# M2Sxxx register map
Vendor: Microsemi; Series: SmartFusion2; File version: 2.0.32
CPU: CM3 r2p1, little endian, MPU, no FPU, 4 interrupt priority bits
Registers are 32-bit, read-write, no defined reset value unless marked. A register's access mark holds for its fields unless they carry their own. Offsets are from the block's base; [hi:lo] are bit positions; {n}, {i} and the like mark numbered series.

## Ethernet_MAC — No description provided for this peripheral
Base 0x40041000
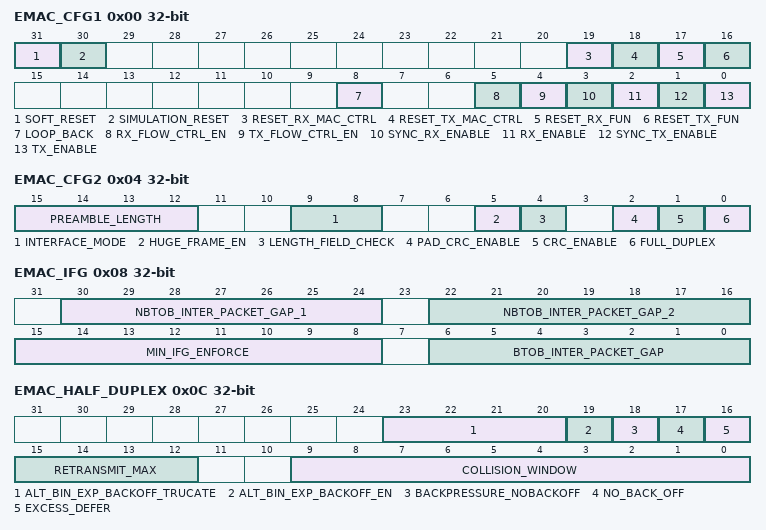
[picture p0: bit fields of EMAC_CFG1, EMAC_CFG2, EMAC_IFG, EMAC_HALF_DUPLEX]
0x00 EMAC_CFG1 — No description provided for this register
  [31] SOFT_RESET — No description provided for this field
  [30] SIMULATION_RESET — No description provided for this field
  [19] RESET_RX_MAC_CTRL — No description provided for this field
  [18] RESET_TX_MAC_CTRL — No description provided for this field
  [17] RESET_RX_FUN — No description provided for this field
  [16] RESET_TX_FUN — No description provided for this field
  [8] LOOP_BACK — No description provided for this field
  [5] RX_FLOW_CTRL_EN — No description provided for this field
  [4] TX_FLOW_CTRL_EN — No description provided for this field
  [3] SYNC_RX_ENABLE — No description provided for this field
  [2] RX_ENABLE — No description provided for this field
  [1] SYNC_TX_ENABLE — No description provided for this field
  [0] TX_ENABLE — No description provided for this field
0x04 EMAC_CFG2 — No description provided for this register
  [15:12] PREAMBLE_LENGTH — No description provided for this field
  [9:8] INTERFACE_MODE — No description provided for this field
  [5] HUGE_FRAME_EN — No description provided for this field
  [4] LENGTH_FIELD_CHECK — No description provided for this field
  [2] PAD_CRC_ENABLE — No description provided for this field
  [1] CRC_ENABLE — No description provided for this field
  [0] FULL_DUPLEX — No description provided for this field
0x08 EMAC_IFG — No description provided for this register
  [30:24] NBTOB_INTER_PACKET_GAP_1 — No description provided for this field
  [22:16] NBTOB_INTER_PACKET_GAP_2 — No description provided for this field
  [15:8] MIN_IFG_ENFORCE — No description provided for this field
  [6:0] BTOB_INTER_PACKET_GAP — No description provided for this field
0x0C EMAC_HALF_DUPLEX — No description provided for this register
  [23:20] ALT_BIN_EXP_BACKOFF_TRUCATE — No description provided for this field
  [19] ALT_BIN_EXP_BACKOFF_EN — No description provided for this field
  [18] BACKPRESSURE_NOBACKOFF — No description provided for this field
  [17] NO_BACK_OFF — No description provided for this field
  [16] EXCESS_DEFER — No description provided for this field
  [15:12] RETRANSMIT_MAX — No description provided for this field
  [9:0] COLLISION_WINDOW — No description provided for this field
0x10 EMAC_FRAME_LENGTH — No description provided for this register
  [15:0] MAX_FRAME_LENGTH — No description provided for this field
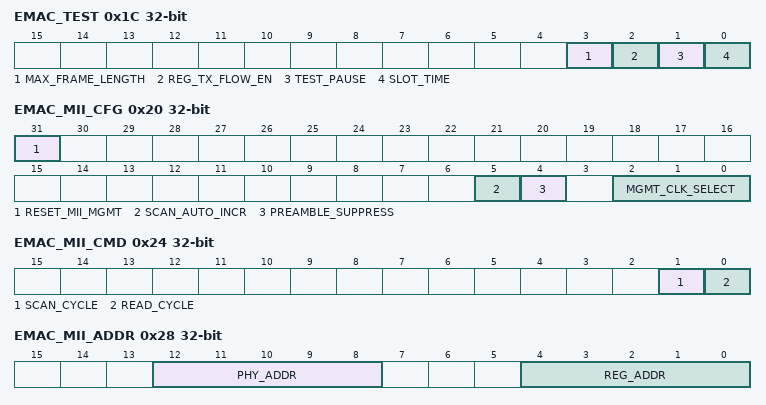
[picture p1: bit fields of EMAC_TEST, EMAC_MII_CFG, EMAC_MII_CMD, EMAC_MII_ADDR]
0x1C EMAC_TEST — No description provided for this register
  [3] MAX_FRAME_LENGTH — No description provided for this field
  [2] REG_TX_FLOW_EN — No description provided for this field
  [1] TEST_PAUSE — No description provided for this field
  [0] SLOT_TIME — No description provided for this field
0x20 EMAC_MII_CFG — No description provided for this register
  [31] RESET_MII_MGMT — No description provided for this field
  [5] SCAN_AUTO_INCR — No description provided for this field
  [4] PREAMBLE_SUPPRESS — No description provided for this field
  [2:0] MGMT_CLK_SELECT — No description provided for this field
0x24 EMAC_MII_CMD — No description provided for this register
  [1] SCAN_CYCLE — No description provided for this field
  [0] READ_CYCLE — No description provided for this field
0x28 EMAC_MII_ADDR — No description provided for this register
  [12:8] PHY_ADDR — No description provided for this field
  [4:0] REG_ADDR — No description provided for this field
0x2C EMAC_MII_CTRL — No description provided for this register
  [15:0] MII_MGMT_CTRL wo — No description provided for this field
0x30 EMAC_MII_STATUS — No description provided for this register
  [15:0] MII_MGMT_STATUS ro — No description provided for this field
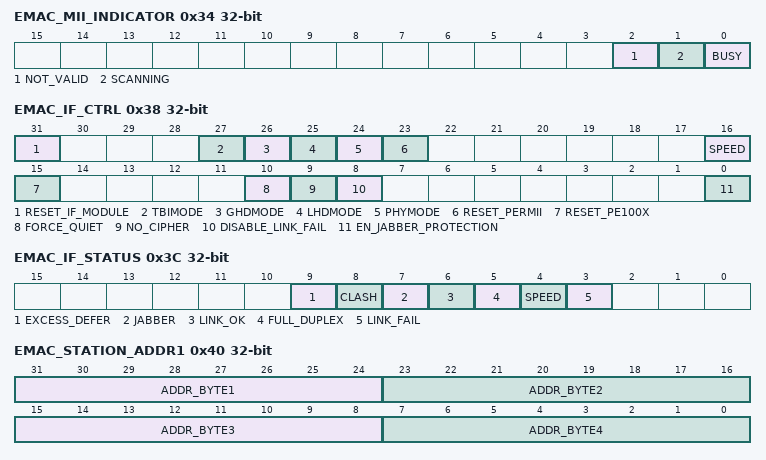
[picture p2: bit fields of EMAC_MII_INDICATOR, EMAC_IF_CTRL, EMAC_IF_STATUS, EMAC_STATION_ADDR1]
0x34 EMAC_MII_INDICATOR — No description provided for this register
  [2] NOT_VALID ro — No description provided for this field
  [1] SCANNING ro — No description provided for this field
  [0] BUSY ro — No description provided for this field
0x38 EMAC_IF_CTRL — No description provided for this register
  [31] RESET_IF_MODULE — No description provided for this field
  [27] TBIMODE — No description provided for this field
  [26] GHDMODE — No description provided for this field
  [25] LHDMODE — No description provided for this field
  [24] PHYMODE — No description provided for this field
  [23] RESET_PERMII — No description provided for this field
  [16] SPEED — No description provided for this field
  [15] RESET_PE100X — No description provided for this field
  [10] FORCE_QUIET — No description provided for this field
  [9] NO_CIPHER — No description provided for this field
  [8] DISABLE_LINK_FAIL — No description provided for this field
  [0] EN_JABBER_PROTECTION — No description provided for this field
0x3C EMAC_IF_STATUS — No description provided for this register
  [9] EXCESS_DEFER ro — No description provided for this field
  [8] CLASH ro — No description provided for this field
  [7] JABBER ro — No description provided for this field
  [6] LINK_OK ro — No description provided for this field
  [5] FULL_DUPLEX ro — No description provided for this field
  [4] SPEED ro — No description provided for this field
  [3] LINK_FAIL ro — No description provided for this field
0x40 EMAC_STATION_ADDR1 — No description provided for this register
  [39-8n:32-8n] ADDR_BYTE{n} (n=1..4) — No description provided for this field
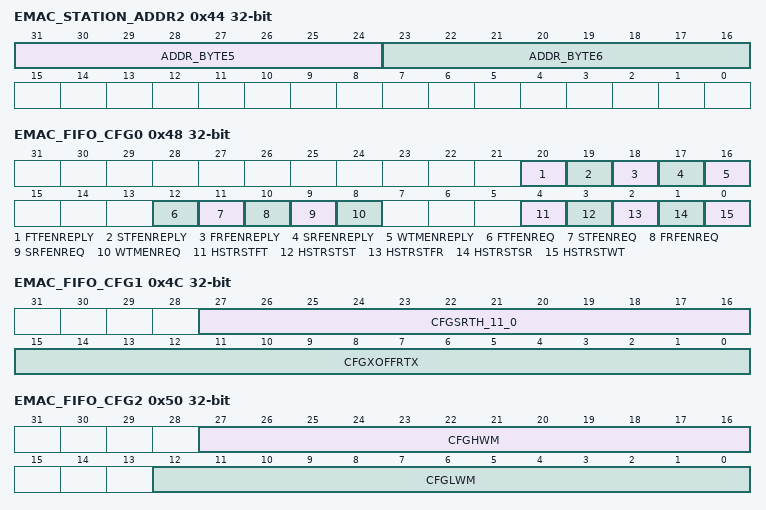
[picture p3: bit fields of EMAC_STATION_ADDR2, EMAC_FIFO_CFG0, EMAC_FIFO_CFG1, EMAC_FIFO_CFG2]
0x44 EMAC_STATION_ADDR2 — No description provided for this register
  [31:24] ADDR_BYTE5 — No description provided for this field
  [23:16] ADDR_BYTE6 — No description provided for this field
0x48 EMAC_FIFO_CFG0 — No description provided for this register
  [20] FTFENREPLY — No description provided for this field
  [19] STFENREPLY — No description provided for this field
  [18] FRFENREPLY — No description provided for this field
  [17] SRFENREPLY — No description provided for this field
  [16] WTMENREPLY — No description provided for this field
  [12] FTFENREQ — No description provided for this field
  [11] STFENREQ — No description provided for this field
  [10] FRFENREQ — No description provided for this field
  [9] SRFENREQ — No description provided for this field
  [8] WTMENREQ — No description provided for this field
  [4] HSTRSTFT — No description provided for this field
  [3] HSTRSTST — No description provided for this field
  [2] HSTRSTFR — No description provided for this field
  [1] HSTRSTSR — No description provided for this field
  [0] HSTRSTWT — No description provided for this field
0x4C EMAC_FIFO_CFG1 — No description provided for this register
  [27:16] CFGSRTH_11_0 — No description provided for this field
  [15:0] CFGXOFFRTX — No description provided for this field
0x50 EMAC_FIFO_CFG2 — No description provided for this register
  [27:16] CFGHWM — No description provided for this field
  [12:0] CFGLWM — No description provided for this field
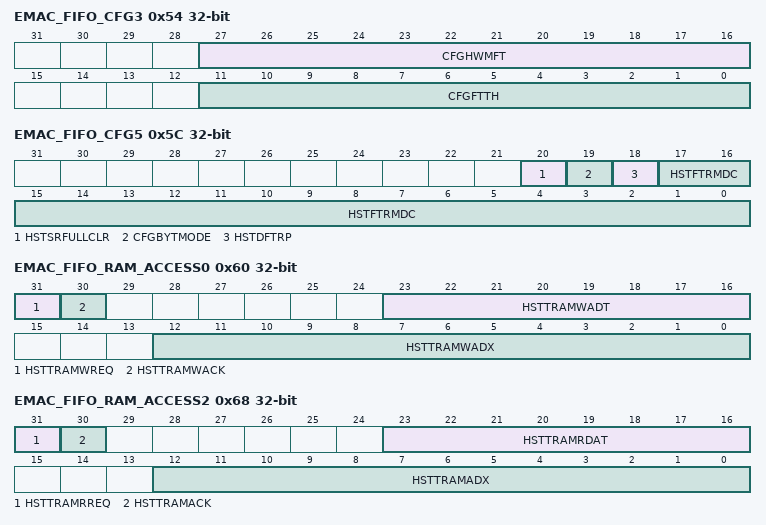
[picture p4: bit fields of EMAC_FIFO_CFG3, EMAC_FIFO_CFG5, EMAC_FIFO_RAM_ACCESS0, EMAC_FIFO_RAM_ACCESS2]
0x54 EMAC_FIFO_CFG3 — No description provided for this register
  [27:16] CFGHWMFT — No description provided for this field
  [11:0] CFGFTTH — No description provided for this field
0x58 EMAC_FIFO_CFG4 — No description provided for this register
  [17:0] HSTFTRFM — No description provided for this field
0x5C EMAC_FIFO_CFG5 — No description provided for this register
  [20] HSTSRFULLCLR — No description provided for this field
  [19] CFGBYTMODE — No description provided for this field
  [18] HSTDFTRP — No description provided for this field
  [17:0] HSTFTRMDC — No description provided for this field
0x60 EMAC_FIFO_RAM_ACCESS0 — No description provided for this register
  [31] HSTTRAMWREQ — No description provided for this field
  [30] HSTTRAMWACK — No description provided for this field
  [23:16] HSTTRAMWADT — No description provided for this field
  [12:0] HSTTRAMWADX — No description provided for this field
0x64 EMAC_FIFO_RAM_ACCESS1 — No description provided for this register
  [31:0] HSTTRAMWDAT — No description provided for this field
0x68 EMAC_FIFO_RAM_ACCESS2 — No description provided for this register
  [31] HSTTRAMRREQ — No description provided for this field
  [30] HSTTRAMACK — No description provided for this field
  [23:16] HSTTRAMRDAT — No description provided for this field
  [12:0] HSTTRAMADX — No description provided for this field
0x6C EMAC_FIFO_RAM_ACCESS3 — No description provided for this register
  [31:0] HSTTRAMRDAT ro — No description provided for this field
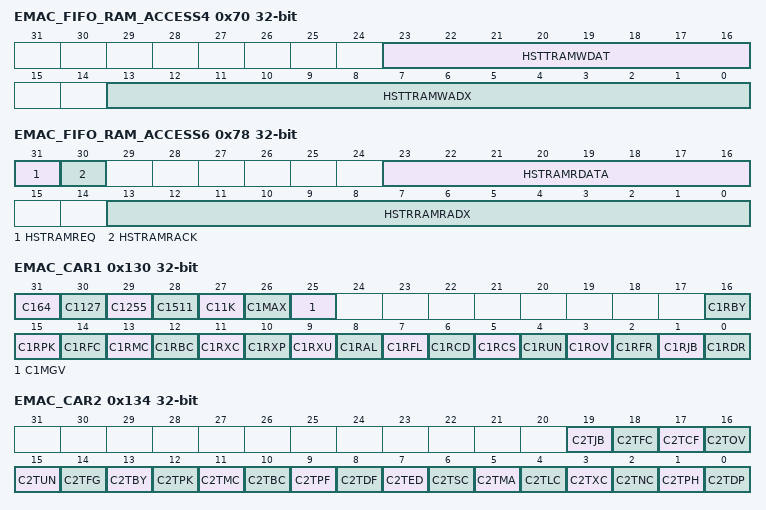
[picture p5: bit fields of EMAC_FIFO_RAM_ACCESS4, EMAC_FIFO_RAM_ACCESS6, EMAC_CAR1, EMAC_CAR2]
0x70 EMAC_FIFO_RAM_ACCESS4 — No description provided for this register
  [23:16] HSTTRAMWDAT — No description provided for this field
  [13:0] HSTTRAMWADX — No description provided for this field
0x74 EMAC_FIFO_RAM_ACCESS5 — No description provided for this register
  [31:0] HSTTRAMWDAT — No description provided for this field
0x78 EMAC_FIFO_RAM_ACCESS6 — No description provided for this register
  [31] HSTRAMREQ — No description provided for this field
  [30] HSTRAMRACK — No description provided for this field
  [23:16] HSTRAMRDATA — No description provided for this field
  [13:0] HSTRRAMRADX — No description provided for this field
0x7C EMAC_FIFO_RAM_ACCESS7 — No description provided for this register
  [31:0] HSTRAMRDAT ro — No description provided for this field
0x80 EMAC_TR64 — No description provided for this register
  [17:0] TR64 — No description provided for this field
0x84 EMAC_TR127 — No description provided for this register
  [17:0] TR127 — No description provided for this field
0x88 EMAC_TR255 — No description provided for this register
  [17:0] TR255 — No description provided for this field
0x8C EMAC_TR511 — No description provided for this register
  [17:0] TR511 — No description provided for this field
0x90 EMAC_TR1K — No description provided for this register
  [17:0] TR1K — No description provided for this field
0x94 EMAC_TRMAX — No description provided for this register
  [17:0] TRMAX — No description provided for this field
0x98 EMAC_TRMGV — No description provided for this register
  [17:0] TRMGV — No description provided for this field
0x9C EMAC_RBYT — No description provided for this register
  [23:0] RBYT — No description provided for this field
0xA0 EMAC_RPKT — No description provided for this register
  [17:0] RPKT — No description provided for this field
0xA4 EMAC_RFCS — No description provided for this register
  [11:0] RFCS — No description provided for this field
0xA8 EMAC_RMCA — No description provided for this register
  [17:0] RMAC — No description provided for this field
0xAC EMAC_RBCA — No description provided for this register
  [21:0] RBCA — No description provided for this field
0xB0 EMAC_RXCF — No description provided for this register
  [17:0] RXCF — No description provided for this field
0xB4 EMAC_RXPF — No description provided for this register
  [11:0] RXPF — No description provided for this field
0xB8 EMAC_RXUO — No description provided for this register
  [11:0] RXUO — No description provided for this field
0xBC EMAC_RALN — No description provided for this register
  [11:0] RALN — No description provided for this field
0xC0 EMAC_RFLR — No description provided for this register
  [15:0] RFLR — No description provided for this field
0xC4 EMAC_RCDE — No description provided for this register
  [11:0] RCDE — No description provided for this field
0xC8 EMAC_RCSE — No description provided for this register
  [11:0] RCSE — No description provided for this field
0xCC EMAC_RUND — No description provided for this register
  [11:0] RUND — No description provided for this field
0xD0 EMAC_ROVR — No description provided for this register
  [11:0] ROVR — No description provided for this field
0xD4 EMAC_RFRG — No description provided for this register
  [11:0] RFRG — No description provided for this field
0xD8 EMAC_RJBR — No description provided for this register
  [11:0] RJBR — No description provided for this field
0xDC EMAC_RDRP — No description provided for this register
  [11:0] RDRP — No description provided for this field
0xE0 EMAC_TBYT — No description provided for this register
  [23:0] TBKT — No description provided for this field
0xE4 EMAC_TPKT — No description provided for this register
  [17:0] TPKT — No description provided for this field
0xE8 EMAC_TMCA — No description provided for this register
  [17:0] TPKT — No description provided for this field
0xEC EMAC_TBCA — No description provided for this register
  [17:0] TBCA — No description provided for this field
0xF0 EMAC_TXPF — No description provided for this register
  [11:0] TXPF — No description provided for this field
0xF4 EMAC_TDFR — No description provided for this register
  [11:0] TDFR — No description provided for this field
0xF8 EMAC_TEDF — No description provided for this register
  [11:0] TEDF — No description provided for this field
0xFC EMAC_TSCL — No description provided for this register
  [11:0] TSCL — No description provided for this field
0x100 EMAC_TMCL — No description provided for this register
  [11:0] TMCL — No description provided for this field
0x104 EMAC_TLCL — No description provided for this register
  [11:0] TLCL — No description provided for this field
0x108 EMAC_TXCL — No description provided for this register
  [11:0] TXCL — No description provided for this field
0x10C EMAC_TNCL — No description provided for this register
  [11:0] TNCL — No description provided for this field
0x110 EMAC_TPFH — No description provided for this register
  [11:0] TPFH — No description provided for this field
0x114 EMAC_TDRP — No description provided for this register
  [11:0] TDRP — No description provided for this field
0x118 EMAC_TJBR — No description provided for this register
  [11:0] TJBR — No description provided for this field
0x11C EMAC_TFCS — No description provided for this register
  [11:0] TFCS — No description provided for this field
0x120 EMAC_TXCF — No description provided for this register
  [11:0] TXCS — No description provided for this field
0x124 EMAC_TOVR — No description provided for this register
  [11:0] TOVR — No description provided for this field
0x128 EMAC_TUND — No description provided for this register
  [11:0] TUND — No description provided for this field
0x12C EMAC_TFRG — No description provided for this register
  [11:0] TFRG — No description provided for this field
0x130 EMAC_CAR1 — No description provided for this register
  [31] C164 ro — No description provided for this field
  [30] C1127 ro — No description provided for this field
  [29] C1255 ro — No description provided for this field
  [28] C1511 ro — No description provided for this field
  [27] C11K ro — No description provided for this field
  [26] C1MAX ro — No description provided for this field
  [25] C1MGV ro — No description provided for this field
  [16] C1RBY ro — No description provided for this field
  [15] C1RPK ro — No description provided for this field
  [14] C1RFC ro — No description provided for this field
  [13] C1RMC ro — No description provided for this field
  [12] C1RBC ro — No description provided for this field
  [11] C1RXC ro — No description provided for this field
  [10] C1RXP ro — No description provided for this field
  [9] C1RXU ro — No description provided for this field
  [8] C1RAL ro — No description provided for this field
  [7] C1RFL ro — No description provided for this field
  [6] C1RCD ro — No description provided for this field
  [5] C1RCS ro — No description provided for this field
  [4] C1RUN ro — No description provided for this field
  [3] C1ROV ro — No description provided for this field
  [2] C1RFR ro — No description provided for this field
  [1] C1RJB ro — No description provided for this field
  [0] C1RDR ro — No description provided for this field
0x134 EMAC_CAR2 — No description provided for this register
  [19] C2TJB ro — No description provided for this field
  [18] C2TFC ro — No description provided for this field
  [17] C2TCF ro — No description provided for this field
  [16] C2TOV ro — No description provided for this field
  [15] C2TUN ro — No description provided for this field
  [14] C2TFG ro — No description provided for this field
  [13] C2TBY ro — No description provided for this field
  [12] C2TPK ro — No description provided for this field
  [11] C2TMC ro — No description provided for this field
  [10] C2TBC ro — No description provided for this field
  [9] C2TPF ro — No description provided for this field
  [8] C2TDF ro — No description provided for this field
  [7] C2TED ro — No description provided for this field
  [6] C2TSC ro — No description provided for this field
  [5] C2TMA ro — No description provided for this field
  [4] C2TLC ro — No description provided for this field
  [3] C2TXC ro — No description provided for this field
  [2] C2TNC ro — No description provided for this field
  [1] C2TPH ro — No description provided for this field
  [0] C2TDP ro — No description provided for this field
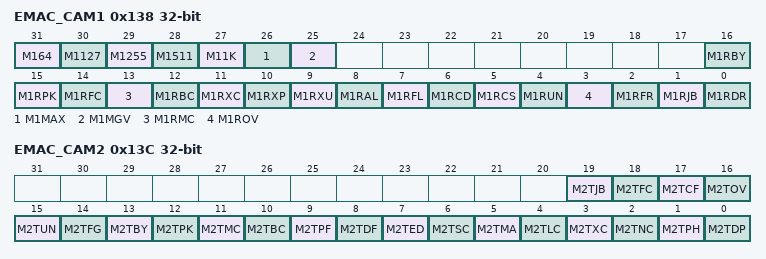
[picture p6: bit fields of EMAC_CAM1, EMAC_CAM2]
0x138 EMAC_CAM1 — No description provided for this register
  [31] M164 — No description provided for this field
  [30] M1127 — No description provided for this field
  [29] M1255 — No description provided for this field
  [28] M1511 — No description provided for this field
  [27] M11K — No description provided for this field
  [26] M1MAX — No description provided for this field
  [25] M1MGV — No description provided for this field
  [16] M1RBY — No description provided for this field
  [15] M1RPK — No description provided for this field
  [14] M1RFC — No description provided for this field
  [13] M1RMC — No description provided for this field
  [12] M1RBC — No description provided for this field
  [11] M1RXC — No description provided for this field
  [10] M1RXP — No description provided for this field
  [9] M1RXU — No description provided for this field
  [8] M1RAL — No description provided for this field
  [7] M1RFL — No description provided for this field
  [6] M1RCD — No description provided for this field
  [5] M1RCS — No description provided for this field
  [4] M1RUN — No description provided for this field
  [3] M1ROV — No description provided for this field
  [2] M1RFR — No description provided for this field
  [1] M1RJB — No description provided for this field
  [0] M1RDR — No description provided for this field
0x13C EMAC_CAM2 — No description provided for this register
  [19] M2TJB — No description provided for this field
  [18] M2TFC — No description provided for this field
  [17] M2TCF — No description provided for this field
  [16] M2TOV — No description provided for this field
  [15] M2TUN — No description provided for this field
  [14] M2TFG — No description provided for this field
  [13] M2TBY — No description provided for this field
  [12] M2TPK — No description provided for this field
  [11] M2TMC — No description provided for this field
  [10] M2TBC — No description provided for this field
  [9] M2TPF — No description provided for this field
  [8] M2TDF — No description provided for this field
  [7] M2TED — No description provided for this field
  [6] M2TSC — No description provided for this field
  [5] M2TMA — No description provided for this field
  [4] M2TLC — No description provided for this field
  [3] M2TXC — No description provided for this field
  [2] M2TNC — No description provided for this field
  [1] M2TPH — No description provided for this field
  [0] M2TDP — No description provided for this field
